# XMC1400 register map
Vendor: Infineon; File version: 1.0.3 (Reference Manual v0.1)
CPU: CM0 r0p0, little endian, no MPU, no FPU, 2 interrupt priority bits
Registers are 32-bit, read-write, reset 0x0 unless marked. A register's access mark holds for its fields unless they carry their own. Offsets are from the block's base; [hi:lo] are bit positions; {n}, {i} and the like mark numbered series.

## LEDTS0 — LED and Touch Sense Unit 0
Base 0x50020000
Same registers: LEDTS1 0x50020400, LEDTS2 0x50020800
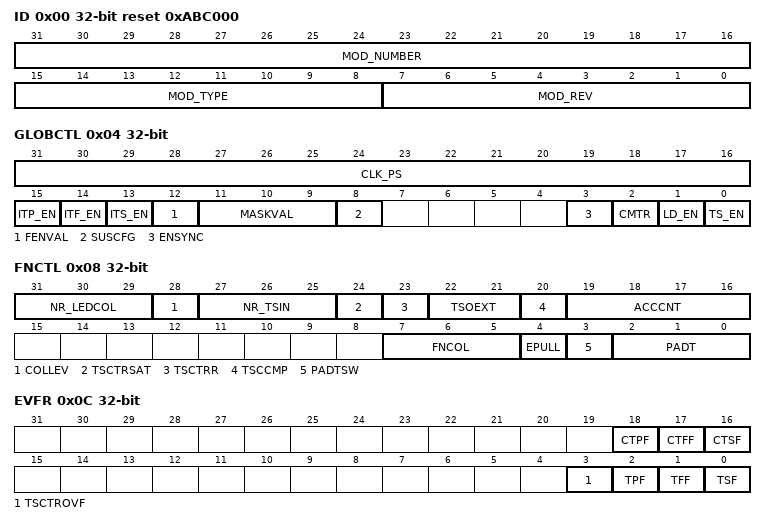
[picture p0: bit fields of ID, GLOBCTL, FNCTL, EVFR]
0x00 ID ro reset 0xABC000 (reset mask 0xFFFFFF00) — Module Identification Register
  [31:16] MOD_NUMBER — Module Number Value
  [15:8] MOD_TYPE — Module Type
  [7:0] MOD_REV — Module Revision Number
0x04 GLOBCTL — Global Control Register
  [31:16] CLK_PS — LEDTS-Counter Clock Pre-Scale Factor
    0=No clock; 1=Divide by 1; 0xFFFF=Divide by 65535
  [15] ITP_EN — Enable Autoscan Time Period Interrupt
    0=Disable; 1=Enable (valid only for case of hardware-enabled pad turn control)
  [14] ITF_EN — Enable (Extended) Time Frame Interrupt
    0=Disable; 1=Enable
  [13] ITS_EN — Enable Time Slice Interrupt
    0=Disable; 1=Enable
  [12] FENVAL — Enable (Extended) Time Frame Validation
    0=Disable; 1=Enable
  [11:9] MASKVAL — Mask Number of LSB Bits for Event Validation
    0=Mask LSB bit; 1=Mask 2 LSB bits; 7=Mask 8 LSB bits
  [8] SUSCFG — Suspend Request Configuration
    0=Ignore suspend request; 1=Enable suspend according to request
  [3] ENSYNC — Enable Autoscan Time Period Synchronization
    0=No synchronization; 1=Synchronization enabled on Kernel0 autoscan time period
  [2] CMTR — Clock Master Disable
    0=Kernel generates its own clock for LEDTS-counter based on SFR setting; 1=LEDTS-counter takes its clock from another master kernel
  [1] LD_EN — LED Function Enable
  [0] TS_EN — Touch-Sense Function Enable
0x08 FNCTL access per field — Function Control Register
  [31:29] NR_LEDCOL rw — Number of LED Columns
    0=1 LED column; {v}={v+1} LED columns (v=1..6); 7=8 LED columns (if bit TS_EN = 1, a maximum number of 7 LED columns is allowed. Combination of TS_EN = 1 and NR_LEDCOL = 111#is disallowed)
  [28] COLLEV rw — Active Level of LED Column
    0=Active low; 1=Active high
  [27:25] NR_TSIN rw — Number of Touch-Sense Input
    0=1; 7=8
  [24] TSCTRSAT rw — Saturation of TS-Counter
    0=Disable; 1=Enable. TS-counter stops counting in the touch-sense time slice(s) of the same (extended) frame when it reaches FFH. Counter starts to count again on the first pad turn of a new TSIN[x], triggered on compare match.
  [23] TSCTRR rw — TS-Counter Auto Reset
    0=Disable TS-counter automatic reset; 1=Enable TS-counter automatic reset to 00H on the first pad turn of a new TSIN[x]. Triggered on compare match in time slice.
  [22:21] TSOEXT rw — Extension for Touch-Sense Output for Pin-Low-Level
    0=Extend by 1 ledts_clk; 1=Extend by 4 ledts_clk; 2=Extend by 8 ledts_clk; 3=Extend by 16 ledts_clk
  [20] TSCCMP rw — Common Compare Enable for Touch-Sense
    0=Disable common compare for touch-sense; 1=Enable common compare for touch-sense
  [19:16] ACCCNT rw — Accumulate Count on Touch-Sense Input
    0=1 time; 1=2 times; 15=16 times
  [7:5] FNCOL ro — Previous Active Function/LED Column Status
  [4] EPULL rw — Enable External Pull-up Configuration on Pin COLA
    0=HW over-rule to enable internal pull-up is active on TSIN[x] for set duration in touch-sense time slice. With this setting, it is not specified to assign the COLA to any pin.; 1=Enable external pull-up: Output 1 on pin COLA for whole duration of touch-sense time slice
  [3] PADTSW rw — Software Control for Touch-Sense Pad Turn
    0=The hardware automatically enables the touch-sense inputs in sequence round-robin, starting from TSIN0; 1=Disable hardware control for software control only. The touch-sense input is configured in bit PADT.
  [2:0] PADT rw — Touch-Sense TSIN Pad Turn
    0=TSIN0; 7=TSIN7
0x0C EVFR access per field — Event Flag Register
  [18] CTPF wo — Clear Autoscan Time Period Interrupt Flag
    0=No action; 1=Bit TPF is cleared
  [17] CTFF wo — Clear (Extended) Time Frame Interrupt Flag
    0=No action; 1=Bit TFF is cleared
  [16] CTSF wo — Clear Time Slice Interrupt Flag
    0=No action; 1=Bit TSF is cleared
  [3] TSCTROVF ro — TS-Counter Overflow Indication
    0=No overflow has occurred; 1=The TS-counter has overflowed at least once
  [2] TPF ro — Autoscan Time Period Interrupt Flag
  [1] TFF ro — (Extended) Time Frame Interrupt Flag
  [0] TSF ro — Time Slice Interrupt Flag
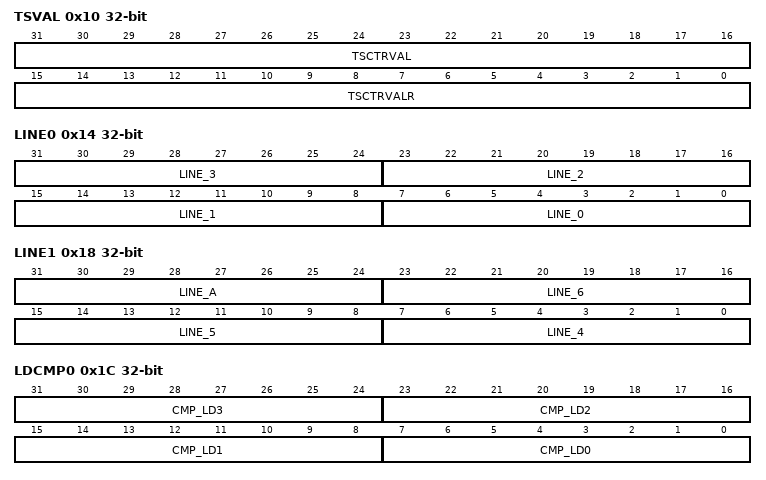
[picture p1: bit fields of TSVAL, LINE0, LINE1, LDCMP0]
0x10 TSVAL access per field — Touch-sense TS-Counter Value
  [31:16] TSCTRVAL rw — TS-Counter Value
  [15:0] TSCTRVALR ro — Shadow TS-Counter Value (Read)
0x14 LINE0 — Line Pattern Register 0
  [8n+7:8n] LINE_{n} (n=0..3) — Output on LINE[x]
0x18 LINE1 — Line Pattern Register 1
  [31:24] LINE_A — Output on LINE[x]
  [23:16] LINE_6 — Output on LINE[x]
  [15:8] LINE_5 — Output on LINE[x]
  [7:0] LINE_4 — Output on LINE[x]
0x1C LDCMP0 — LED Compare Register 0
  [8n+7:8n] CMP_LD{n} (n=0..3) — Compare Value for LED COL[x]
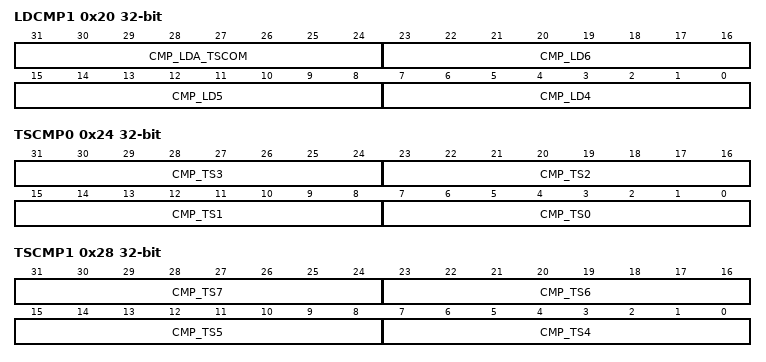
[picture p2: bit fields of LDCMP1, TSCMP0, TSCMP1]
0x20 LDCMP1 — LED Compare Register 1
  [31:24] CMP_LDA_TSCOM — Compare Value for LED COLA / Common Compare Value for Touch-sense Pad Turns
  [23:16] CMP_LD6 — Compare Value for LED COL[x]
  [15:8] CMP_LD5 — Compare Value for LED COL[x]
  [7:0] CMP_LD4 — Compare Value for LED COL[x]
0x24 TSCMP0 — Touch-sense Compare Register 0
  [8n+7:8n] CMP_TS{n} (n=0..3) — Compare Value for Touch-Sense TSIN[x]
0x28 TSCMP1 — Touch-sense Compare Register 1
  [8n-25:8n-32] CMP_TS{n} (n=4..7) — Compare Value for Touch-Sense TSIN[x]
